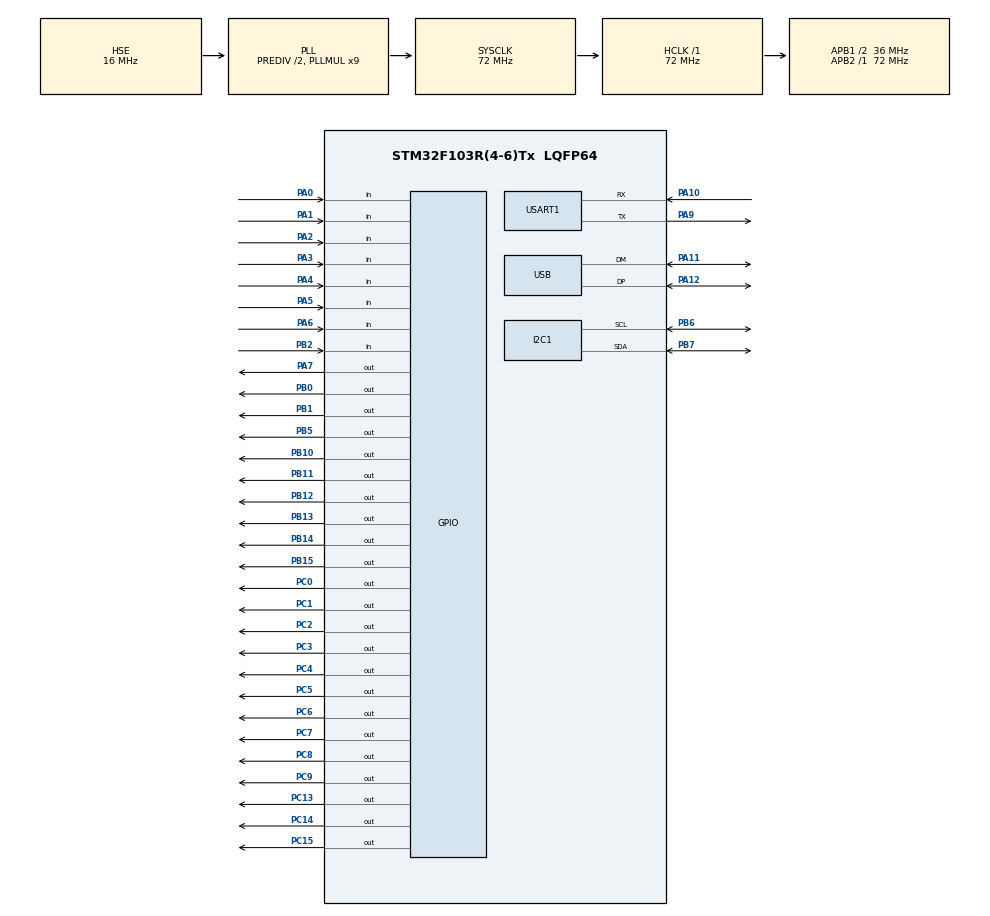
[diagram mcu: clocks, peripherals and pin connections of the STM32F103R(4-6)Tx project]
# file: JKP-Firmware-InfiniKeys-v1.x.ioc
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Mcu.Family=STM32F1
Mcu.Name=STM32F103R(4-6)Tx
Mcu.Package=LQFP64
NVIC.PriorityGroup=NVIC_PRIORITYGROUP_4
NVIC.TIM1_UP_IRQn=true\:0\:0\:false\:false\:true\:false\:true
NVIC.TimeBase=TIM1_UP_IRQn
NVIC.TimeBaseIP=TIM1
NVIC.USB_LP_CAN1_RX0_IRQn=true\:0\:0\:false\:false\:true\:false\:true
PA0-WKUP.GPIO_PuPd=GPIO_PULLDOWN
PA0-WKUP.Signal=GPIO_Input
PA1.GPIO_PuPd=GPIO_PULLDOWN
PA1.Signal=GPIO_Input
PA10.Mode=Asynchronous
PA10.Signal=USART1_RX
PA11.Mode=Device
PA11.Signal=USB_DM
PA12.Mode=Device
PA12.Signal=USB_DP
PA13.Mode=Serial_Wire
PA13.Signal=SYS_JTMS-SWDIO
PA14.Mode=Serial_Wire
PA14.Signal=SYS_JTCK-SWCLK
PA2.GPIO_PuPd=GPIO_PULLDOWN
PA2.Signal=GPIO_Input
PA3.GPIO_PuPd=GPIO_PULLDOWN
PA3.Signal=GPIO_Input
PA4.GPIO_PuPd=GPIO_PULLDOWN
PA4.Signal=GPIO_Input
PA5.GPIO_PuPd=GPIO_PULLDOWN
PA5.Signal=GPIO_Input
PA6.GPIO_PuPd=GPIO_PULLDOWN
PA6.Signal=GPIO_Input
PA7.Signal=GPIO_Output
PA9.Mode=Asynchronous
PA9.Signal=USART1_TX
PB0.Signal=GPIO_Output
PB1.Signal=GPIO_Output
PB10.Signal=GPIO_Output
PB11.Signal=GPIO_Output
PB12.Signal=GPIO_Output
PB13.Signal=GPIO_Output
PB14.Signal=GPIO_Output
PB15.Signal=GPIO_Output
PB2.Signal=GPIO_Input
PB5.Signal=GPIO_Output
PB6.Mode=I2C
PB6.Signal=I2C1_SCL
PB7.Mode=I2C
PB7.Signal=I2C1_SDA
PC0.Signal=GPIO_Output
PC1.Signal=GPIO_Output
PC13-TAMPER-RTC.Signal=GPIO_Output
PC14-OSC32_IN.Signal=GPIO_Output
PC15-OSC32_OUT.Signal=GPIO_Output
PC2.Signal=GPIO_Output
PC3.Signal=GPIO_Output
PC4.Signal=GPIO_Output
PC5.Signal=GPIO_Output
PC6.Signal=GPIO_Output
PC7.Signal=GPIO_Output
PC8.Signal=GPIO_Output
PC9.Signal=GPIO_Output
PD0-OSC_IN.Mode=HSE-External-Oscillator
PD0-OSC_IN.Signal=RCC_OSC_IN
PD1-OSC_OUT.Mode=HSE-External-Oscillator
PD1-OSC_OUT.Signal=RCC_OSC_OUT
ProjectManager.HeapSize=0x200
ProjectManager.StackSize=0x400
ProjectManager.TargetToolchain=TrueSTUDIO
RCC.AHBFreq_Value=72000000
RCC.APB1CLKDivider=RCC_HCLK_DIV2
RCC.APB1Freq_Value=36000000
RCC.APB1TimFreq_Value=72000000
RCC.APB2Freq_Value=72000000
RCC.APB2TimFreq_Value=72000000
RCC.HCLKFreq_Value=72000000
RCC.HSEDivPLL=RCC_HSE_PREDIV_DIV2
RCC.HSE_VALUE=16000000
RCC.PLLMUL=RCC_PLL_MUL9
RCC.PLLSourceVirtual=RCC_PLLSOURCE_HSE
RCC.SYSCLKFreq_VALUE=72000000
RCC.SYSCLKSource=RCC_SYSCLKSOURCE_PLLCLK
RCC.USBFreq_Value=48000000
RCC.USBPrescaler=RCC_USBCLKSOURCE_PLL_DIV1_5
USART1.VirtualMode=VM_ASYNC
USB_DEVICE.CLASS_NAME_FS=CUSTOM_HID
USB_DEVICE.MANUFACTURER_STRING=Johannes Berndorfer
USB_DEVICE.PID_CUSTOMHID_FS=1024
USB_DEVICE.PRODUCT_STRING_CUSTOMHID_FS=JKP Programmer Keyboard
USB_DEVICE.VirtualMode=CustomHid
USB_DEVICE.VirtualModeFS=Custom_Hid_FS
VP_SYS_VS_tim1.Mode=TIM1
VP_USB_DEVICE_VS_USB_DEVICE_CUSTOM_HID_FS.Mode=CUSTOM_HID_FS
board=custom

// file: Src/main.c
/* USER CODE BEGIN Header */
/**
  ******************************************************************************
  * @file           : main.c
  * @brief          : Main program body
  ******************************************************************************
  * @attention
  *
  * <h2><center>&copy; Copyright (c) 2019 STMicroelectronics.
  * All rights reserved.</center></h2>
  *
  * This software component is licensed by ST under Ultimate Liberty license
  * SLA0044, the "License"; You may not use this file except in compliance with
  * the License. You may obtain a copy of the License at:
  *                             www.st.com/SLA0044
  *
  ******************************************************************************
  */
/* USER CODE END Header */

#include "main.h"
#include "usb_device.h"

/* USER CODE BEGIN Includes */
#include "fwmain.h"
/* USER CODE END Includes */

I2C_HandleTypeDef hi2c1;

UART_HandleTypeDef huart1;

void SystemClock_Config(void);
static void MX_GPIO_Init(void);
static void MX_I2C1_Init(void);
static void MX_USART1_UART_Init(void);

int main(void)
{

  /* MCU Configuration--------------------------------------------------------*/

  /* Reset of all peripherals, Initializes the Flash interface and the Systick. */
  HAL_Init();

  /* Configure the system clock */
  SystemClock_Config();

  /* Initialize all configured peripherals */
  MX_GPIO_Init();
  MX_I2C1_Init();
  MX_USART1_UART_Init();
  MX_USB_DEVICE_Init();
  /* USER CODE BEGIN 2 */
  FW_Setup();
  /* USER CODE END 2 */

  /* Infinite loop */
  /* USER CODE BEGIN WHILE */
  FW_Exec();
  /* USER CODE END 3 */
}

void SystemClock_Config(void)
{
  RCC_OscInitTypeDef RCC_OscInitStruct = {0};
  RCC_ClkInitTypeDef RCC_ClkInitStruct = {0};
  RCC_PeriphCLKInitTypeDef PeriphClkInit = {0};

  /** Initializes the CPU, AHB and APB busses clocks
  */
  RCC_OscInitStruct.OscillatorType = RCC_OSCILLATORTYPE_HSE;
  RCC_OscInitStruct.HSEState = RCC_HSE_ON;
  RCC_OscInitStruct.HSEPredivValue = RCC_HSE_PREDIV_DIV2;
  RCC_OscInitStruct.HSIState = RCC_HSI_ON;
  RCC_OscInitStruct.PLL.PLLState = RCC_PLL_ON;
  RCC_OscInitStruct.PLL.PLLSource = RCC_PLLSOURCE_HSE;
  RCC_OscInitStruct.PLL.PLLMUL = RCC_PLL_MUL9;
  if (HAL_RCC_OscConfig(&RCC_OscInitStruct) != HAL_OK)
  {
    Error_Handler();
  }
  /** Initializes the CPU, AHB and APB busses clocks
  */
  RCC_ClkInitStruct.ClockType = RCC_CLOCKTYPE_HCLK|RCC_CLOCKTYPE_SYSCLK
                              |RCC_CLOCKTYPE_PCLK1|RCC_CLOCKTYPE_PCLK2;
  RCC_ClkInitStruct.SYSCLKSource = RCC_SYSCLKSOURCE_PLLCLK;
  RCC_ClkInitStruct.AHBCLKDivider = RCC_SYSCLK_DIV1;
  RCC_ClkInitStruct.APB1CLKDivider = RCC_HCLK_DIV2;
  RCC_ClkInitStruct.APB2CLKDivider = RCC_HCLK_DIV1;

  if (HAL_RCC_ClockConfig(&RCC_ClkInitStruct, FLASH_LATENCY_2) != HAL_OK)
  {
    Error_Handler();
  }
  PeriphClkInit.PeriphClockSelection = RCC_PERIPHCLK_USB;
  PeriphClkInit.UsbClockSelection = RCC_USBCLKSOURCE_PLL_DIV1_5;
  if (HAL_RCCEx_PeriphCLKConfig(&PeriphClkInit) != HAL_OK)
  {
    Error_Handler();
  }
}

static void MX_I2C1_Init(void)
{

  hi2c1.Instance = I2C1;
  hi2c1.Init.ClockSpeed = 100000;
  hi2c1.Init.DutyCycle = I2C_DUTYCYCLE_2;
  hi2c1.Init.OwnAddress1 = 0;
  hi2c1.Init.AddressingMode = I2C_ADDRESSINGMODE_7BIT;
  hi2c1.Init.DualAddressMode = I2C_DUALADDRESS_DISABLE;
  hi2c1.Init.OwnAddress2 = 0;
  hi2c1.Init.GeneralCallMode = I2C_GENERALCALL_DISABLE;
  hi2c1.Init.NoStretchMode = I2C_NOSTRETCH_DISABLE;
  if (HAL_I2C_Init(&hi2c1) != HAL_OK)
  {
    Error_Handler();
  }

}

static void MX_USART1_UART_Init(void)
{

  huart1.Instance = USART1;
  huart1.Init.BaudRate = 115200;
  huart1.Init.WordLength = UART_WORDLENGTH_8B;
  huart1.Init.StopBits = UART_STOPBITS_1;
  huart1.Init.Parity = UART_PARITY_NONE;
  huart1.Init.Mode = UART_MODE_TX_RX;
  huart1.Init.HwFlowCtl = UART_HWCONTROL_NONE;
  huart1.Init.OverSampling = UART_OVERSAMPLING_16;
  if (HAL_UART_Init(&huart1) != HAL_OK)
  {
    Error_Handler();
  }

}

static void MX_GPIO_Init(void)
{
  GPIO_InitTypeDef GPIO_InitStruct = {0};

  /* GPIO Ports Clock Enable */
  __HAL_RCC_GPIOC_CLK_ENABLE();
  __HAL_RCC_GPIOD_CLK_ENABLE();
  __HAL_RCC_GPIOA_CLK_ENABLE();
  __HAL_RCC_GPIOB_CLK_ENABLE();

  /*Configure GPIO pin Output Level */
  HAL_GPIO_WritePin(GPIOC, GPIO_PIN_13|GPIO_PIN_14|GPIO_PIN_15|GPIO_PIN_0
                          |GPIO_PIN_1|GPIO_PIN_2|GPIO_PIN_3|GPIO_PIN_4
                          |GPIO_PIN_5|GPIO_PIN_6|GPIO_PIN_7|GPIO_PIN_8
                          |GPIO_PIN_9, GPIO_PIN_RESET);

  /*Configure GPIO pin Output Level */
  HAL_GPIO_WritePin(GPIOA, GPIO_PIN_7, GPIO_PIN_RESET);

  /*Configure GPIO pin Output Level */
  HAL_GPIO_WritePin(GPIOB, GPIO_PIN_0|GPIO_PIN_1|GPIO_PIN_10|GPIO_PIN_11
                          |GPIO_PIN_12|GPIO_PIN_13|GPIO_PIN_14|GPIO_PIN_15
                          |GPIO_PIN_5, GPIO_PIN_RESET);

  /*Configure GPIO pins : PC13 PC14 PC15 PC0
                           PC1 PC2 PC3 PC4
                           PC5 PC6 PC7 PC8
                           PC9 */
  GPIO_InitStruct.Pin = GPIO_PIN_13|GPIO_PIN_14|GPIO_PIN_15|GPIO_PIN_0
                          |GPIO_PIN_1|GPIO_PIN_2|GPIO_PIN_3|GPIO_PIN_4
                          |GPIO_PIN_5|GPIO_PIN_6|GPIO_PIN_7|GPIO_PIN_8
                          |GPIO_PIN_9;
  GPIO_InitStruct.Mode = GPIO_MODE_OUTPUT_PP;
  GPIO_InitStruct.Pull = GPIO_NOPULL;
  GPIO_InitStruct.Speed = GPIO_SPEED_FREQ_LOW;
  HAL_GPIO_Init(GPIOC, &GPIO_InitStruct);

  /*Configure GPIO pins : PA0 PA1 PA2 PA3
                           PA4 PA5 PA6 */
  GPIO_InitStruct.Pin = GPIO_PIN_0|GPIO_PIN_1|GPIO_PIN_2|GPIO_PIN_3
                          |GPIO_PIN_4|GPIO_PIN_5|GPIO_PIN_6;
  GPIO_InitStruct.Mode = GPIO_MODE_INPUT;
  GPIO_InitStruct.Pull = GPIO_PULLDOWN;
  HAL_GPIO_Init(GPIOA, &GPIO_InitStruct);

  /*Configure GPIO pin : PA7 */
  GPIO_InitStruct.Pin = GPIO_PIN_7;
  GPIO_InitStruct.Mode = GPIO_MODE_OUTPUT_PP;
  GPIO_InitStruct.Pull = GPIO_NOPULL;
  GPIO_InitStruct.Speed = GPIO_SPEED_FREQ_LOW;
  HAL_GPIO_Init(GPIOA, &GPIO_InitStruct);

  /*Configure GPIO pins : PB0 PB1 PB10 PB11
                           PB12 PB13 PB14 PB15
                           PB5 */
  GPIO_InitStruct.Pin = GPIO_PIN_0|GPIO_PIN_1|GPIO_PIN_10|GPIO_PIN_11
                          |GPIO_PIN_12|GPIO_PIN_13|GPIO_PIN_14|GPIO_PIN_15
                          |GPIO_PIN_5;
  GPIO_InitStruct.Mode = GPIO_MODE_OUTPUT_PP;
  GPIO_InitStruct.Pull = GPIO_NOPULL;
  GPIO_InitStruct.Speed = GPIO_SPEED_FREQ_LOW;
  HAL_GPIO_Init(GPIOB, &GPIO_InitStruct);

  /*Configure GPIO pin : PB2 */
  GPIO_InitStruct.Pin = GPIO_PIN_2;
  GPIO_InitStruct.Mode = GPIO_MODE_INPUT;
  GPIO_InitStruct.Pull = GPIO_NOPULL;
  HAL_GPIO_Init(GPIOB, &GPIO_InitStruct);

}

void HAL_TIM_PeriodElapsedCallback(TIM_HandleTypeDef *htim)
{
  if (htim->Instance == TIM1) {
    HAL_IncTick();
  }
}

void Error_Handler(void)
{
}

/************************ (C) COPYRIGHT STMicroelectronics *****END OF FILE****/
